# STM32H7A3AGI6Q register map
File version: 1.0
Registers are 32-bit, access not given, reset 0x0 unless marked. A register's access mark holds for its fields unless they carry their own. Offsets are from the block's base; [hi:lo] are bit positions; {n}, {i} and the like mark numbered series; 'fields as' and 'values as' point back to an identical list.

## FLASH
Base 0x52002000
0x04 KEYR1
  [31:0] KEY1R
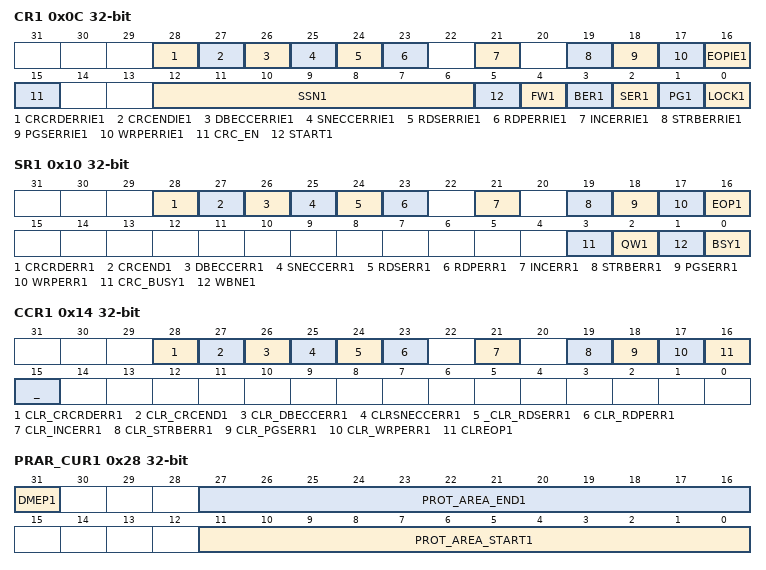
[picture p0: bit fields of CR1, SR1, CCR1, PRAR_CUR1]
0x0C CR1
  [28] CRCRDERRIE1, [27] CRCENDIE1, [26] DBECCERRIE1, [25] SNECCERRIE1, [24] RDSERRIE1, [23] RDPERRIE1, [21] INCERRIE1, [19] STRBERRIE1, [18] PGSERRIE1, [17] WRPERRIE1, [16] EOPIE1, [15] CRC_EN, [12:6] SSN1, [5] START1, [4] FW1, [3] BER1, [2] SER1, [1] PG1, [0] LOCK1
0x10 SR1
  [28] CRCRDERR1, [27] CRCEND1, [26] DBECCERR1, [25] SNECCERR1, [24] RDSERR1, [23] RDPERR1, [21] INCERR1, [19] STRBERR1, [18] PGSERR1, [17] WRPERR1, [16] EOP1, [3] CRC_BUSY1, [2] QW1, [1] WBNE1, [0] BSY1
0x14 CCR1
  [28] CLR_CRCRDERR1, [27] CLR_CRCEND1, [26] CLR_DBECCERR1, [25] CLRSNECCERR1, [24] _CLR_RDSERR1, [23] CLR_RDPERR1, [21] CLR_INCERR1, [19] CLR_STRBERR1, [18] CLR_PGSERR1, [17] CLR_WRPERR1, [16] CLREOP1, [15] _
0x28 PRAR_CUR1
  [31] DMEP1, [27:16] PROT_AREA_END1, [11:0] PROT_AREA_START1
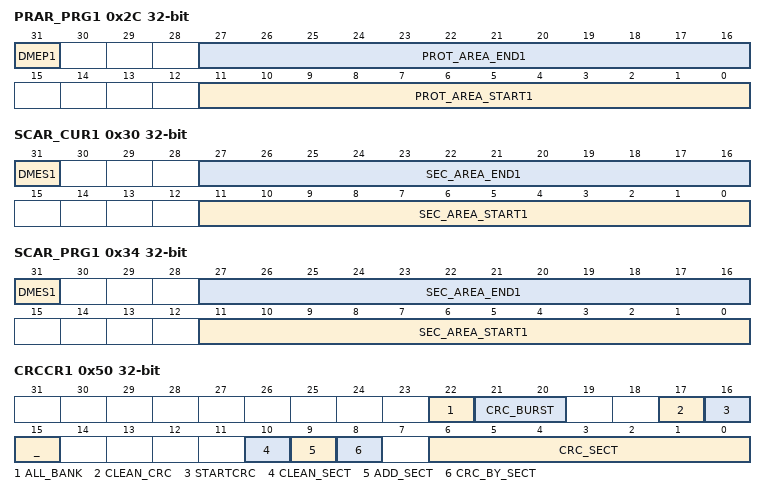
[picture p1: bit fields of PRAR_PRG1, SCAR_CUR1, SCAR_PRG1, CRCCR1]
0x2C PRAR_PRG1
  [31] DMEP1, [27:16] PROT_AREA_END1, [11:0] PROT_AREA_START1
0x30 SCAR_CUR1
  [31] DMES1, [27:16] SEC_AREA_END1, [11:0] SEC_AREA_START1
0x34 SCAR_PRG1
  [31] DMES1, [27:16] SEC_AREA_END1, [11:0] SEC_AREA_START1
0x38 WPSGN_CUR1R
  [31:0] WRPSGn1
0x3C WPSGN_PRG1R
  [31:0] WRPSGn1
0x50 CRCCR1
  [22] ALL_BANK, [21:20] CRC_BURST, [17] CLEAN_CRC, [16] STARTCRC, [15] _, [10] CLEAN_SECT, [9] ADD_SECT, [8] CRC_BY_SECT, [6:0] CRC_SECT
0x54 CRCSADD1R
  [19:2] CRC_START_ADDR
0x58 CRCEADD1R
  [19:2] CRC_END_ADDR
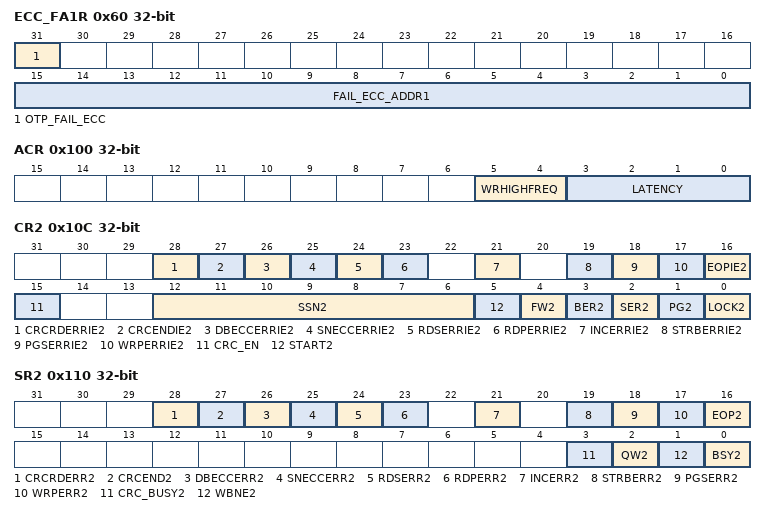
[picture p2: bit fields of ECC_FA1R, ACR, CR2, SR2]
0x60 ECC_FA1R
  [31] OTP_FAIL_ECC, [15:0] FAIL_ECC_ADDR1
0x68 OTPBL_CUR
  [15:0] LOCKBL
0x6C OTPBL_PRG
  [15:0] LOCKBL
0x100 ACR
  [5:4] WRHIGHFREQ, [3:0] LATENCY
0x104 KEYR2
  [31:0] KEY2R
0x108 OPTKEYR
0x10C CR2
  [28] CRCRDERRIE2, [27] CRCENDIE2, [26] DBECCERRIE2, [25] SNECCERRIE2, [24] RDSERRIE2, [23] RDPERRIE2, [21] INCERRIE2, [19] STRBERRIE2, [18] PGSERRIE2, [17] WRPERRIE2, [16] EOPIE2, [15] CRC_EN, [12:6] SSN2, [5] START2, [4] FW2, [3] BER2, [2] SER2, [1] PG2, [0] LOCK2
0x110 SR2
  [28] CRCRDERR2, [27] CRCEND2, [26] DBECCERR2, [25] SNECCERR2, [24] RDSERR2, [23] RDPERR2, [21] INCERR2, [19] STRBERR2, [18] PGSERR2, [17] WRPERR2, [16] EOP2, [3] CRC_BUSY2, [2] QW2, [1] WBNE2, [0] BSY2
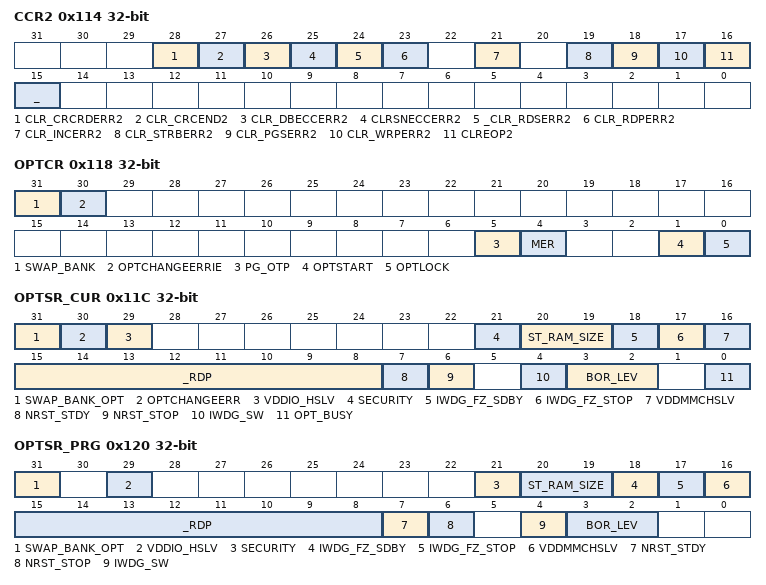
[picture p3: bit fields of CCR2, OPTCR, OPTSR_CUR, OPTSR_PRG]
0x114 CCR2
  [28] CLR_CRCRDERR2, [27] CLR_CRCEND2, [26] CLR_DBECCERR2, [25] CLRSNECCERR2, [24] _CLR_RDSERR2, [23] CLR_RDPERR2, [21] CLR_INCERR2, [19] CLR_STRBERR2, [18] CLR_PGSERR2, [17] CLR_WRPERR2, [16] CLREOP2, [15] _
0x118 OPTCR
  [31] SWAP_BANK, [30] OPTCHANGEERRIE, [5] PG_OTP, [4] MER, [1] OPTSTART, [0] OPTLOCK
0x11C OPTSR_CUR
  [31] SWAP_BANK_OPT, [30] OPTCHANGEERR, [29] VDDIO_HSLV, [21] SECURITY, [20:19] ST_RAM_SIZE, [18] IWDG_FZ_SDBY, [17] IWDG_FZ_STOP, [16] VDDMMCHSLV, [15:8] _RDP, [7] NRST_STDY, [6] NRST_STOP, [4] IWDG_SW, [3:2] BOR_LEV, [0] OPT_BUSY
0x120 OPTSR_PRG
  [31] SWAP_BANK_OPT, [29] VDDIO_HSLV, [21] SECURITY, [20:19] ST_RAM_SIZE, [18] IWDG_FZ_SDBY, [17] IWDG_FZ_STOP, [16] VDDMMCHSLV, [15:8] _RDP, [7] NRST_STDY, [6] NRST_STOP, [4] IWDG_SW, [3:2] BOR_LEV
0x124 OPTCCR
  [30] CLR_OPTCHANGEERR
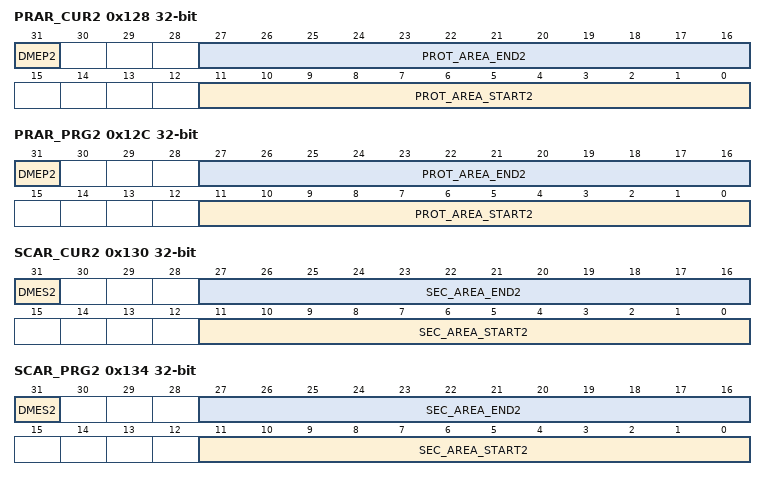
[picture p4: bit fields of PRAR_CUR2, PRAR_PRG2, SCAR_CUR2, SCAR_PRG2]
0x128 PRAR_CUR2
  [31] DMEP2, [27:16] PROT_AREA_END2, [11:0] PROT_AREA_START2
0x12C PRAR_PRG2
  [31] DMEP2, [27:16] PROT_AREA_END2, [11:0] PROT_AREA_START2
0x130 SCAR_CUR2
  [31] DMES2, [27:16] SEC_AREA_END2, [11:0] SEC_AREA_START2
0x134 SCAR_PRG2
  [31] DMES2, [27:16] SEC_AREA_END2, [11:0] SEC_AREA_START2
0x138 WPSGN_CUR2R
  [31:0] WRPSGn2
0x13C WPSGN_PRG2R
  [31:0] WRPSGn2
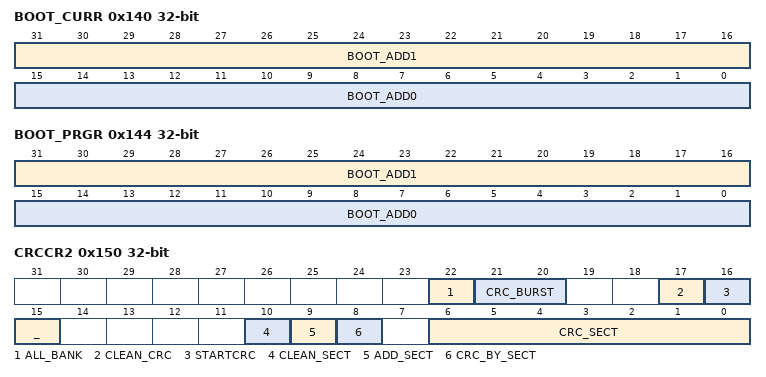
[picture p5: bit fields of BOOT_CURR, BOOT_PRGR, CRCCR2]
0x140 BOOT_CURR
  [31:16] BOOT_ADD1, [15:0] BOOT_ADD0
0x144 BOOT_PRGR
  [31:16] BOOT_ADD1, [15:0] BOOT_ADD0
0x150 CRCCR2
  fields as CRCCR1
0x154 CRCSADD2R
  [19:2] CRC_START_ADDR
0x158 CRCEADD2R
  [19:2] CRC_END_ADDR
0x15C CRCDATAR
  [31:0] CRC_DATA
0x160 ECC_FA2R
  [15:0] FAIL_ECC_ADDR2

## FMC
Base 0x52004000
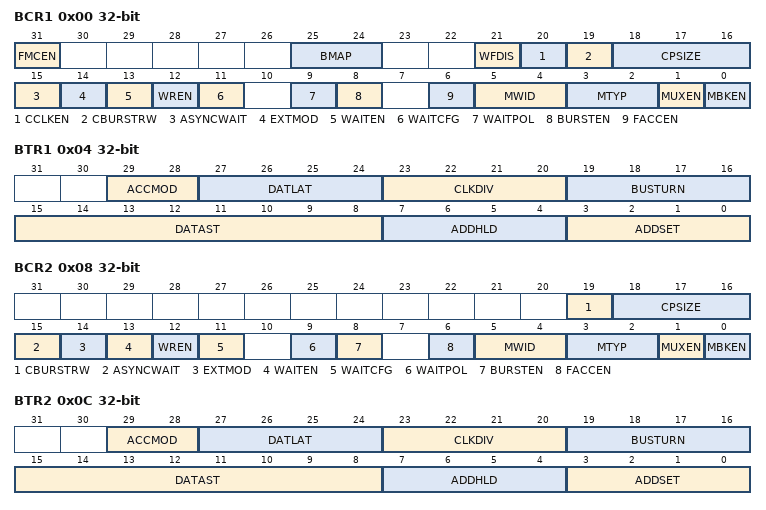
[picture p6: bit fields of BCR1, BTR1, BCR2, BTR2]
0x00 BCR1
  [31] FMCEN, [25:24] BMAP, [21] WFDIS, [20] CCLKEN, [19] CBURSTRW, [18:16] CPSIZE, [15] ASYNCWAIT, [14] EXTMOD, [13] WAITEN, [12] WREN, [11] WAITCFG, [9] WAITPOL, [8] BURSTEN, [6] FACCEN, [5:4] MWID, [3:2] MTYP, [1] MUXEN, [0] MBKEN
0x04 BTR1
  [29:28] ACCMOD, [27:24] DATLAT, [23:20] CLKDIV, [19:16] BUSTURN, [15:8] DATAST, [7:4] ADDHLD, [3:0] ADDSET
0x08 BCR2
  [19] CBURSTRW, [18:16] CPSIZE, [15] ASYNCWAIT, [14] EXTMOD, [13] WAITEN, [12] WREN, [11] WAITCFG, [9] WAITPOL, [8] BURSTEN, [6] FACCEN, [5:4] MWID, [3:2] MTYP, [1] MUXEN, [0] MBKEN
0x0C BTR2
  fields as BTR1
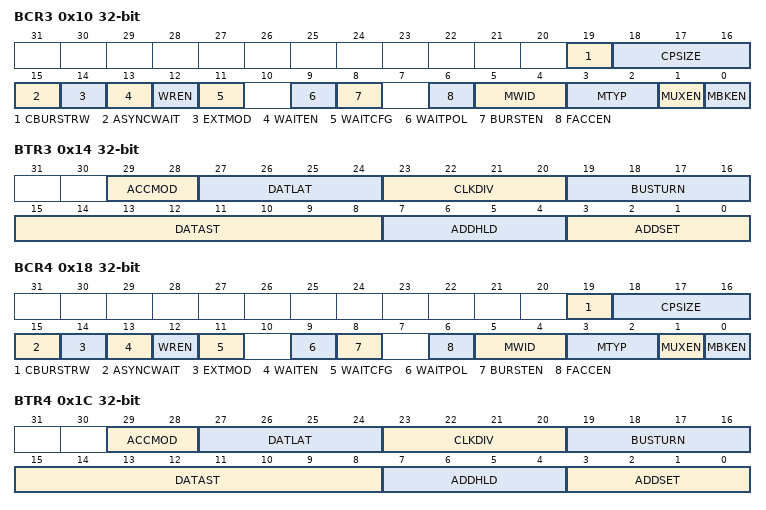
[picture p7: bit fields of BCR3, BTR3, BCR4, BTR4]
0x10 BCR3
  fields as BCR2
0x14 BTR3
  fields as BTR1
0x18 BCR4
  fields as BCR2
0x1C BTR4
  fields as BTR1
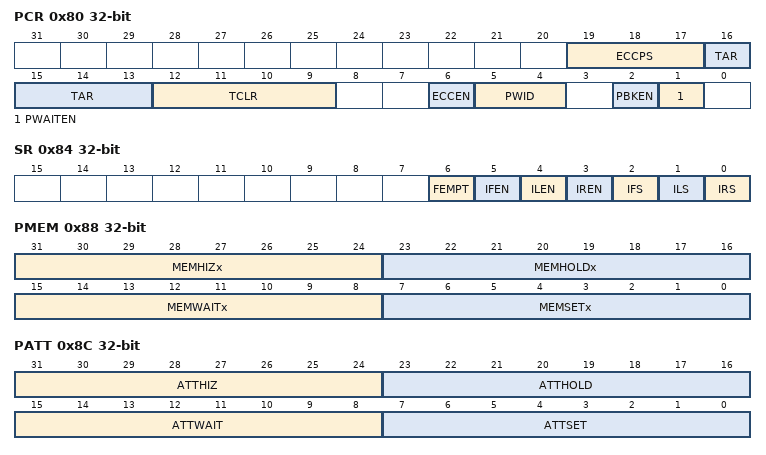
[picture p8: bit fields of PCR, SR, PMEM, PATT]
0x80 PCR
  [19:17] ECCPS, [16:13] TAR, [12:9] TCLR, [6] ECCEN, [5:4] PWID, [2] PBKEN, [1] PWAITEN
0x84 SR
  [6] FEMPT, [5] IFEN, [4] ILEN, [3] IREN, [2] IFS, [1] ILS, [0] IRS
0x88 PMEM
  [31:24] MEMHIZx, [23:16] MEMHOLDx, [15:8] MEMWAITx, [7:0] MEMSETx
0x8C PATT
  [31:24] ATTHIZ, [23:16] ATTHOLD, [15:8] ATTWAIT, [7:0] ATTSET
0x94 ECCR
  [31:0] ECC
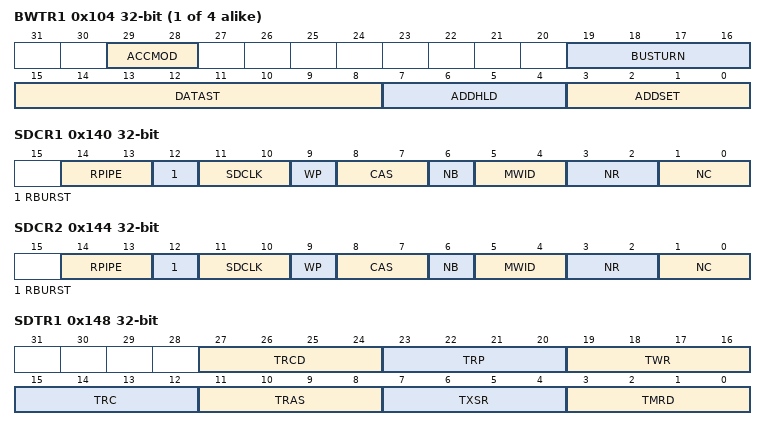
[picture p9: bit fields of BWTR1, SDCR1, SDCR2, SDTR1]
{0xFC+8i} BWTR{i} (i=1..4)
  [29:28] ACCMOD, [19:16] BUSTURN, [15:8] DATAST, [7:4] ADDHLD, [3:0] ADDSET
0x140 SDCR1
  [14:13] RPIPE, [12] RBURST, [11:10] SDCLK, [9] WP, [8:7] CAS, [6] NB, [5:4] MWID, [3:2] NR, [1:0] NC
0x144 SDCR2
  fields as SDCR1
0x148 SDTR1
  [27:24] TRCD, [23:20] TRP, [19:16] TWR, [15:12] TRC, [11:8] TRAS, [7:4] TXSR, [3:0] TMRD
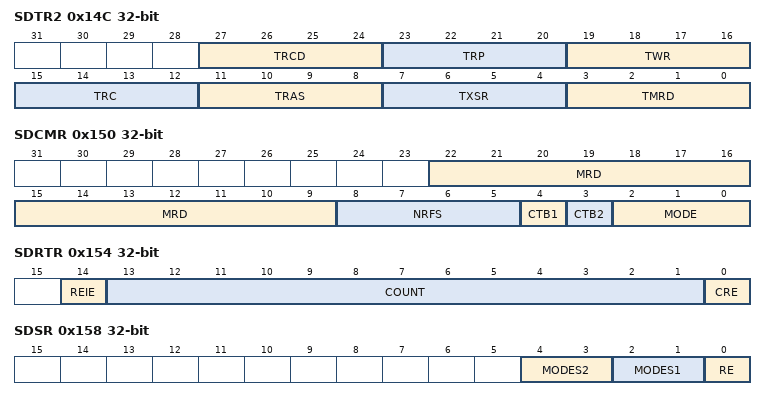
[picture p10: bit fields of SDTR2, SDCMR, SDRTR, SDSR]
0x14C SDTR2
  fields as SDTR1
0x150 SDCMR
  [22:9] MRD, [8:5] NRFS, [4] CTB1, [3] CTB2, [2:0] MODE
0x154 SDRTR
  [14] REIE, [13:1] COUNT, [0] CRE
0x158 SDSR
  [4:3] MODES2, [2:1] MODES1, [0] RE
